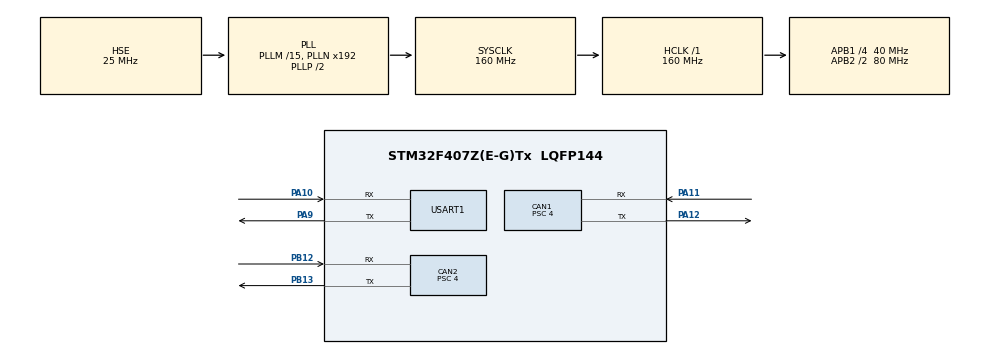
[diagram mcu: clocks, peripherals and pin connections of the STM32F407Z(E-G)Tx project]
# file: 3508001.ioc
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CAN1.BS1=CAN_BS1_5TQ
CAN1.BS2=CAN_BS2_4TQ
CAN1.CalculateBaudRate=1000000
CAN1.CalculateTimeBit=1000
CAN1.CalculateTimeQuantum=100.0
CAN1.Prescaler=4
CAN2.BS1=CAN_BS1_5TQ
CAN2.BS2=CAN_BS2_4TQ
CAN2.CalculateBaudRate=1000000
CAN2.CalculateTimeBit=1000
CAN2.CalculateTimeQuantum=100.0
CAN2.Prescaler=4
Mcu.Family=STM32F4
Mcu.Name=STM32F407Z(E-G)Tx
Mcu.Package=LQFP144
NVIC.CAN1_RX0_IRQn=true\:0\:0\:false\:false\:true\:true\:true\:true
NVIC.CAN2_RX1_IRQn=true\:0\:0\:false\:false\:true\:true\:true\:true
NVIC.PriorityGroup=NVIC_PRIORITYGROUP_4
PA10.Mode=Asynchronous
PA10.Signal=USART1_RX
PA11.Mode=CAN_Activate
PA11.Signal=CAN1_RX
PA12.Mode=CAN_Activate
PA12.Signal=CAN1_TX
PA13.Mode=Serial_Wire
PA13.Signal=SYS_JTMS-SWDIO
PA14.Mode=Serial_Wire
PA14.Signal=SYS_JTCK-SWCLK
PA9.Mode=Asynchronous
PA9.Signal=USART1_TX
PB12.Mode=CAN_Activate
PB12.Signal=CAN2_RX
PB13.Mode=CAN_Activate
PB13.Signal=CAN2_TX
PC14-OSC32_IN.Mode=LSE-External-Oscillator
PC14-OSC32_IN.Signal=RCC_OSC32_IN
PC15-OSC32_OUT.Mode=LSE-External-Oscillator
PC15-OSC32_OUT.Signal=RCC_OSC32_OUT
PH0-OSC_IN.Mode=HSE-External-Oscillator
PH0-OSC_IN.Signal=RCC_OSC_IN
PH1-OSC_OUT.Mode=HSE-External-Oscillator
PH1-OSC_OUT.Signal=RCC_OSC_OUT
ProjectManager.HeapSize=0x200
ProjectManager.StackSize=0x400
ProjectManager.TargetToolchain=MDK-ARM V5.32
RCC.48MHZClocksFreq_Value=80000000
RCC.AHBFreq_Value=160000000
RCC.APB1CLKDivider=RCC_HCLK_DIV4
RCC.APB1Freq_Value=40000000
RCC.APB1TimFreq_Value=80000000
RCC.APB2CLKDivider=RCC_HCLK_DIV2
RCC.APB2Freq_Value=80000000
RCC.APB2TimFreq_Value=160000000
RCC.CortexFreq_Value=160000000
RCC.HCLKFreq_Value=160000000
RCC.HSE_VALUE=25000000
RCC.HSI_VALUE=16000000
RCC.PLLM=15
RCC.PLLSourceVirtual=RCC_PLLSOURCE_HSE
RCC.SYSCLKFreq_VALUE=160000000
RCC.SYSCLKSource=RCC_SYSCLKSOURCE_PLLCLK
RCC.VCOOutputFreq_Value=320000000
USART1.VirtualMode=VM_ASYNC
board=custom

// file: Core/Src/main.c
/* USER CODE BEGIN Header */
/**
  ******************************************************************************
  * @file           : main.c
  * @brief          : Main program body
  ******************************************************************************
  * @attention
  *
  * Copyright (c) 2023 STMicroelectronics.
  * All rights reserved.
  *
  * This software is licensed under terms that can be found in the LICENSE file
  * in the root directory of this software component.
  * If no LICENSE file comes with this software, it is provided AS-IS.
  *
  ******************************************************************************
  */
/* USER CODE END Header */
#include "main.h"
#include "can.h"
#include "usart.h"
#include "gpio.h"

/* USER CODE BEGIN Includes */
#include "RM3508.h"
#include "can_bsp.h"
/* USER CODE END Includes */

void SystemClock_Config(void);

int main(void)
{

  /* MCU Configuration--------------------------------------------------------*/

  /* Reset of all peripherals, Initializes the Flash interface and the Systick. */
  HAL_Init();

  /* Configure the system clock */
  SystemClock_Config();

  /* Initialize all configured peripherals */
  MX_GPIO_Init();
  MX_CAN1_Init();
  MX_CAN2_Init();
  MX_USART1_UART_Init();
  /* USER CODE BEGIN 2 */
	CAN_Init(&hcan2);
  /* USER CODE END 2 */

  /* Infinite loop */
  while (1)
  {
		RM3508_Set_Pos(8192,4);
		int pos=RM3508_Get_Pos(4);

		printf("%d,%d\n",pos,720);
		HAL_Delay(0);
  }
}

void SystemClock_Config(void)
{
  RCC_OscInitTypeDef RCC_OscInitStruct = {0};
  RCC_ClkInitTypeDef RCC_ClkInitStruct = {0};

  /** Configure the main internal regulator output voltage
  */
  __HAL_RCC_PWR_CLK_ENABLE();
  __HAL_PWR_VOLTAGESCALING_CONFIG(PWR_REGULATOR_VOLTAGE_SCALE1);

  /** Initializes the RCC Oscillators according to the specified parameters
  * in the RCC_OscInitTypeDef structure.
  */
  RCC_OscInitStruct.OscillatorType = RCC_OSCILLATORTYPE_HSE;
  RCC_OscInitStruct.HSEState = RCC_HSE_ON;
  RCC_OscInitStruct.PLL.PLLState = RCC_PLL_ON;
  RCC_OscInitStruct.PLL.PLLSource = RCC_PLLSOURCE_HSE;
  RCC_OscInitStruct.PLL.PLLM = 15;
  RCC_OscInitStruct.PLL.PLLN = 192;
  RCC_OscInitStruct.PLL.PLLP = RCC_PLLP_DIV2;
  RCC_OscInitStruct.PLL.PLLQ = 4;
  if (HAL_RCC_OscConfig(&RCC_OscInitStruct) != HAL_OK)
  {
    Error_Handler();
  }

  /** Initializes the CPU, AHB and APB buses clocks
  */
  RCC_ClkInitStruct.ClockType = RCC_CLOCKTYPE_HCLK|RCC_CLOCKTYPE_SYSCLK
                              |RCC_CLOCKTYPE_PCLK1|RCC_CLOCKTYPE_PCLK2;
  RCC_ClkInitStruct.SYSCLKSource = RCC_SYSCLKSOURCE_PLLCLK;
  RCC_ClkInitStruct.AHBCLKDivider = RCC_SYSCLK_DIV1;
  RCC_ClkInitStruct.APB1CLKDivider = RCC_HCLK_DIV4;
  RCC_ClkInitStruct.APB2CLKDivider = RCC_HCLK_DIV2;

  if (HAL_RCC_ClockConfig(&RCC_ClkInitStruct, FLASH_LATENCY_5) != HAL_OK)
  {
    Error_Handler();
  }
}

void Error_Handler(void)
{
  __disable_irq();
  while (1)
  {
  }
}
